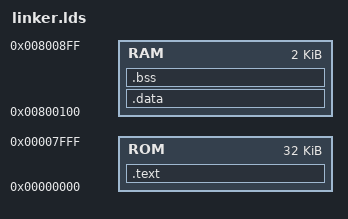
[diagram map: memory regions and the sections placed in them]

ENTRY(_start)

MEMORY
{
        ROM : ORIGIN = 0x0000, LENGTH = 0x8000
        RAM : ORIGIN = 0x800100, LENGTH = 0x0800
}

SECTIONS
{
        /**********************************************************************
         *                                                                    *
         **********************************************************************/
        .text :
        {
                _stext = .;
                *(.vectors)
                *(.startup)
                *(.text)
                *(.text.*)
                /* *(.rodata) */
                /* *(.rodata.*) */
                *(.eh_frame)
                . = ALIGN(0x2);
                _etext = .;
        } > ROM
        /**********************************************************************
         *                                                                    *
         **********************************************************************/
        .data : AT(_etext)
        {
                _sdata = .;
                *(.rodata)
                *(.rodata.*)
                *(.data)
                *(.data.*)
                *(.sdata)
                *(.sdata.*)
                . = ALIGN(0x10);
                _edata = .;
        } > RAM
        /**********************************************************************
         *                                                                    *
         **********************************************************************/
        .bss ADDR(.data) + SIZEOF(.data) (NOLOAD) :
        {
                _sbss = .;
                *(.bss)
                *(.bss.*)
                *(COMMON)
                *(.sbss)
                *(.sbss.*)
                /* *(.scommon) */
                /* *(.dynbss) */
                . = ALIGN(0x10);
                _ebss = .;
        } > RAM
        /**********************************************************************
         *                                                                    *
         **********************************************************************/
        /DISCARD/ :
        {
                *(.comment)
        }
}

